# dsPIC33FJ64GS606 register map
Vendor: Microchip; Series: dsPIC33FJ64GS; File version: 1.4.228
Registers are 16-bit, read-write, no defined reset value unless marked. A register's access mark holds for its fields unless they carry their own. Offsets are from the block's base; [hi:lo] are bit positions; {n}, {i} and the like mark numbered series.

## GPIO_CN — GPIO_CN peripheral registers
Base 0x00000060
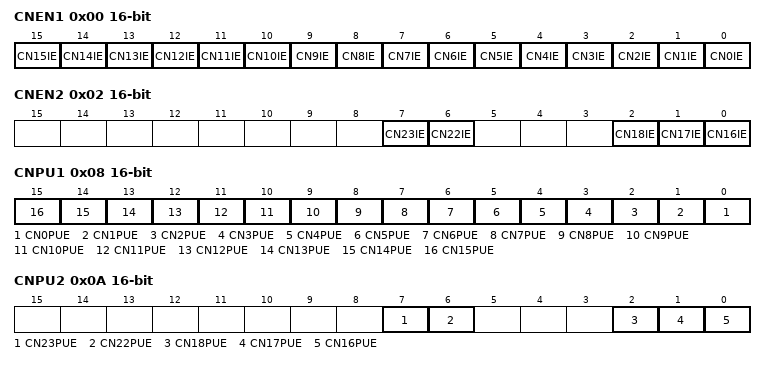
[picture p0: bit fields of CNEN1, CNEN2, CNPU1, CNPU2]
0x00 CNEN1
  [n] CN{n}IE (n=0..15) — CNEN1 field CN{n}IE
0x02 CNEN2
  [7] CN23IE — CNEN2 field CN23IE
  [6] CN22IE — CNEN2 field CN22IE
  [2] CN18IE — CNEN2 field CN18IE
  [1] CN17IE — CNEN2 field CN17IE
  [0] CN16IE — CNEN2 field CN16IE
0x08 CNPU1
  [n] CN{n}PUE (n=0..15) — CNPU1 field CN{n}PUE
0x0A CNPU2
  [7] CN23PUE — CNPU2 field CN23PUE
  [6] CN22PUE — CNPU2 field CN22PUE
  [2] CN18PUE — CNPU2 field CN18PUE
  [1] CN17PUE — CNPU2 field CN17PUE
  [0] CN16PUE — CNPU2 field CN16PUE

## TIMER1 — TIMER1 peripheral registers
Base 0x00000100
0x00 TMR1
  [15:0] TMR1 — TMR1 register value
0x02 PR1
  [15:0] PR1 — PR1 register value
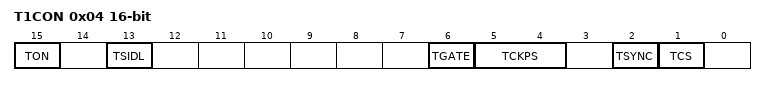
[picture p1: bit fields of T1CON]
0x04 T1CON
  [15] TON — Timer1 On bit
  [13] TSIDL — Timer1 stop in Idle mode bit
  [6] TGATE — Timer1 gated time accumulation enable bit
  [5:4] TCKPS — Timer1 input clock prescale select bits
  [2] TSYNC — Timer1 external clock input synchronization select bit
  [1] TCS — Timer1 clock source select bit

## TIMER2 — TIMER2 peripheral registers
Base 0x00000106
0x00 TMR2
  [15:0] TMR2 — TMR2 register value
0x06 PR2
  [15:0] PR2 — PR2 register value
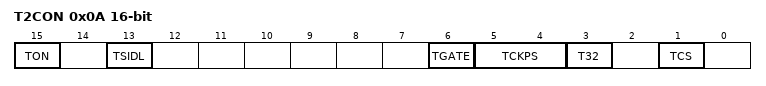
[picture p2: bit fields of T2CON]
0x0A T2CON
  [15] TON — T2 On bit
  [13] TSIDL — T2 stop in Idle mode bit
  [6] TGATE — T2 gated time accumulation enable bit
  [5:4] TCKPS — T2 input clock prescale select bits
  [3] T32 — Timer2 and Timer3 32-bit mode select bit
  [1] TCS — T2 clock source select bit

## TIMER3 — TIMER3 peripheral registers
Base 0x00000108
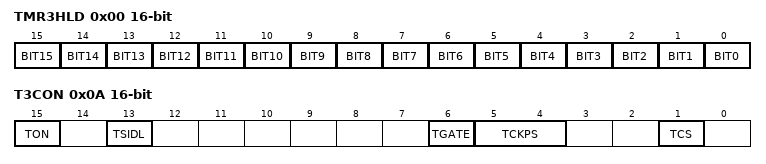
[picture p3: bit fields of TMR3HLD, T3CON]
0x00 TMR3HLD
  [n] BIT{n} (n=0..15) — TMR3HLD bit {n}
0x02 TMR3
  [15:0] TMR3 — TMR3 register value
0x06 PR3
  [15:0] PR3 — PR3 register value
0x0A T3CON
  [15] TON — T3 On bit
  [13] TSIDL — T3 stop in Idle mode bit
  [6] TGATE — T3 gated time accumulation enable bit
  [5:4] TCKPS — T3 input clock prescale select bits
  [1] TCS — T3 clock source select bit

## TIMER4 — TIMER4 peripheral registers
Base 0x00000114
0x00 TMR4
  [15:0] TMR4 — TMR4 register value
0x06 PR4
  [15:0] PR4 — PR4 register value
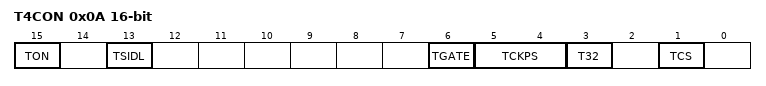
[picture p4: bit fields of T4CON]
0x0A T4CON
  [15] TON — T4 On bit
  [13] TSIDL — T4 stop in Idle mode bit
  [6] TGATE — T4 gated time accumulation enable bit
  [5:4] TCKPS — T4 input clock prescale select bits
  [3] T32 — Timer4 and Timer5 32-bit mode select bit
  [1] TCS — T4 clock source select bit

## TIMER5 — TIMER5 peripheral registers
Base 0x00000116
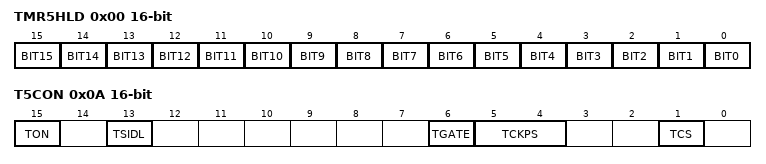
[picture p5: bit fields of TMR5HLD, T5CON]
0x00 TMR5HLD
  [n] BIT{n} (n=0..15) — TMR5HLD bit {n}
0x02 TMR5
  [15:0] TMR5 — TMR5 register value
0x06 PR5
  [15:0] PR5 — PR5 register value
0x0A T5CON
  [15] TON — T5 On bit
  [13] TSIDL — T5 stop in Idle mode bit
  [6] TGATE — T5 gated time accumulation enable bit
  [5:4] TCKPS — T5 input clock prescale select bits
  [1] TCS — T5 clock source select bit

## IC1 — IC1 peripheral registers
Base 0x00000140
0x00 IC1BUF
  [15:0] IC1BUF — IC1BUF register value
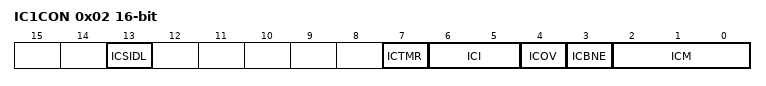
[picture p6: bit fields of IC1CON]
0x02 IC1CON
  [13] ICSIDL — IC1CON field ICSIDL
  [7] ICTMR — IC1CON field ICTMR
  [6:5] ICI — IC1CON field ICI
  [4] ICOV — IC1CON field ICOV
  [3] ICBNE — IC1CON field ICBNE
  [2:0] ICM — IC1CON field ICM

## IC2 — IC2 peripheral registers
Base 0x00000144
Registers as IC1 (with IC1 read as IC2).

## IC3 — IC3 peripheral registers
Base 0x00000148
Registers as IC1 (with IC1 read as IC3).

## IC4 — IC4 peripheral registers
Base 0x0000014C
Registers as IC1 (with IC1 read as IC4).

## OC1 — OC1 peripheral registers
Base 0x00000180
0x00 OC1RS
  [15:0] OC1RS — OC1RS register value
0x02 OC1R
  [15:0] OC1R — OC1R register value
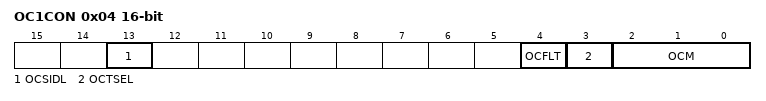
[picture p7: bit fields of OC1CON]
0x04 OC1CON
  [13] OCSIDL — OC1CON field OCSIDL
  [4] OCFLT — OC1CON field OCFLT
  [3] OCTSEL — OC1CON field OCTSEL
  [2:0] OCM — OC1CON field OCM

## OC2 — OC2 peripheral registers
Base 0x00000186
Registers as OC1 (with OC1 read as OC2).

## OC3 — OC3 peripheral registers
Base 0x0000018C
Registers as OC1 (with OC1 read as OC3).

## OC4 — OC4 peripheral registers
Base 0x00000192
Registers as OC1 (with OC1 read as OC4).
